# DDR_CTRL register map
Registers from a debugger description file.
Registers are 32-bit, access not given, no defined reset value unless marked. A register's access mark holds for its fields unless they carry their own. Addresses are absolute; registers are grouped by the start of their names; lines under a group give offsets from that group; [hi:lo] are bit positions; {n}, {i} and the like mark numbered series; 'fields as' and 'values as' point back to an identical list; <NAME> marks a mode.

## DENALI
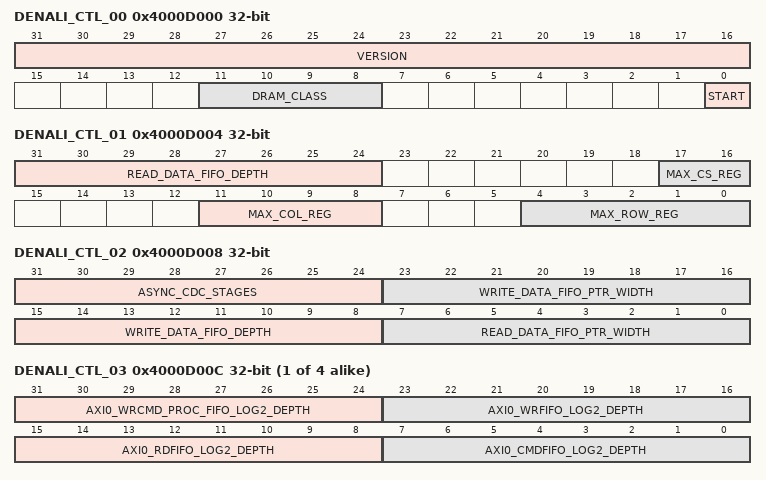
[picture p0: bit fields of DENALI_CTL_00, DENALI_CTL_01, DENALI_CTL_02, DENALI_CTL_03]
0x4000D000 DENALI_CTL_00
  [31:16] VERSION, [11:8] DRAM_CLASS, [0] START
0x4000D004 DENALI_CTL_01 ro
  [31:24] READ_DATA_FIFO_DEPTH, [17:16] MAX_CS_REG, [11:8] MAX_COL_REG, [4:0] MAX_ROW_REG
0x4000D008 DENALI_CTL_02 ro
  [31:24] ASYNC_CDC_STAGES, [23:16] WRITE_DATA_FIFO_PTR_WIDTH, [15:8] WRITE_DATA_FIFO_DEPTH, [7:0] READ_DATA_FIFO_PTR_WIDTH
{0x4000D000+4i} DENALI_CTL_{i:02} ro (i=3..6)
  [31:24] AXI{i-3}_WRCMD_PROC_FIFO_LOG2_DEPTH, [23:16] AXI{i-3}_WRFIFO_LOG2_DEPTH, [15:8] AXI{i-3}_RDFIFO_LOG2_DEPTH, [7:0] AXI{i-3}_CMDFIFO_LOG2_DEPTH
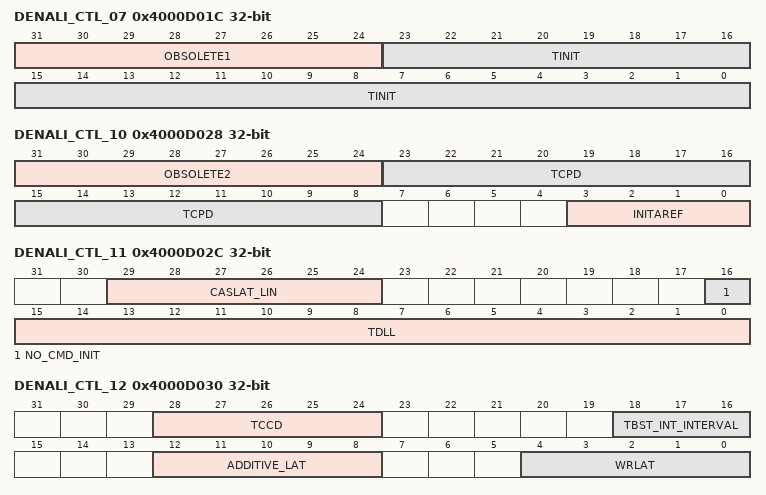
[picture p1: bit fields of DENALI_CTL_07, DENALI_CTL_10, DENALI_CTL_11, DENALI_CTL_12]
0x4000D01C DENALI_CTL_07
  [31:24] OBSOLETE1, [23:0] TINIT
0x4000D020 DENALI_CTL_08
  [31:0] TRST_PWRON
0x4000D024 DENALI_CTL_09
  [31:0] CKE_INACTIVE
0x4000D028 DENALI_CTL_10
  [31:24] OBSOLETE2, [23:8] TCPD, [3:0] INITAREF
0x4000D02C DENALI_CTL_11
  [29:24] CASLAT_LIN, [16] NO_CMD_INIT, [15:0] TDLL
0x4000D030 DENALI_CTL_12
  [28:24] TCCD, [18:16] TBST_INT_INTERVAL, [12:8] ADDITIVE_LAT, [4:0] WRLAT
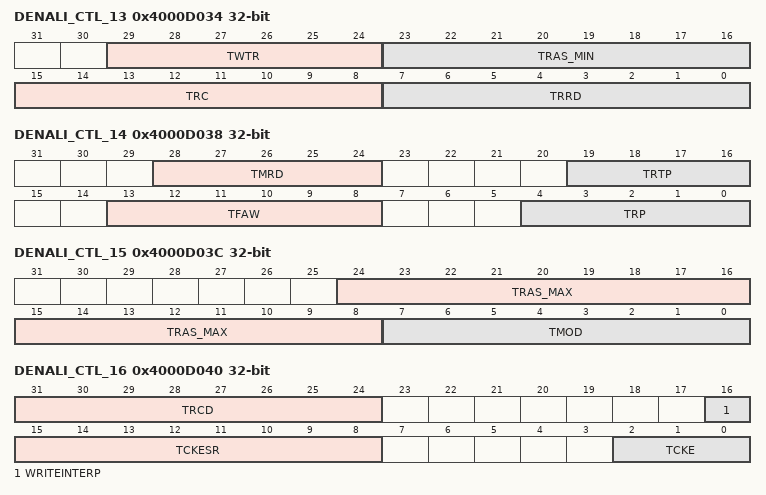
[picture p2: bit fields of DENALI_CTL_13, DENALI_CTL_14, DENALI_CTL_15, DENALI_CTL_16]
0x4000D034 DENALI_CTL_13
  [29:24] TWTR, [23:16] TRAS_MIN, [15:8] TRC, [7:0] TRRD
0x4000D038 DENALI_CTL_14
  [28:24] TMRD, [19:16] TRTP, [13:8] TFAW, [4:0] TRP
0x4000D03C DENALI_CTL_15
  [24:8] TRAS_MAX, [7:0] TMOD
0x4000D040 DENALI_CTL_16
  [31:24] TRCD, [16] WRITEINTERP, [15:8] TCKESR, [2:0] TCKE
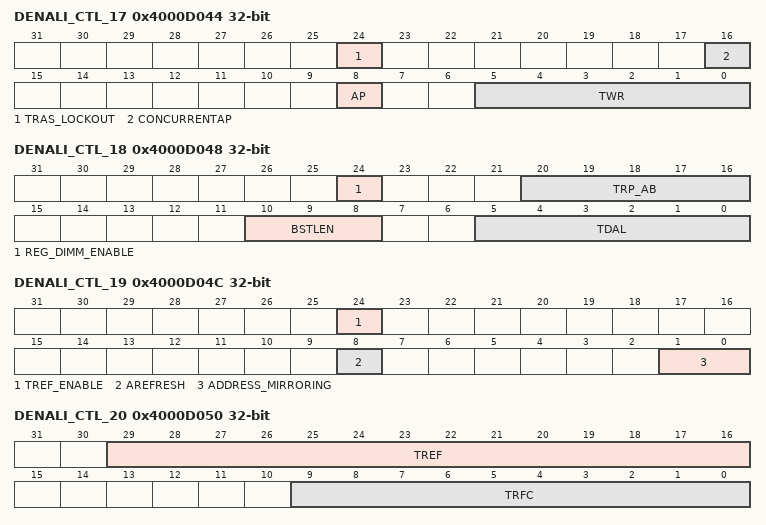
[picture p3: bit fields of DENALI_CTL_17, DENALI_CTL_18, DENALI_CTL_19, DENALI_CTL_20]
0x4000D044 DENALI_CTL_17
  [24] TRAS_LOCKOUT, [16] CONCURRENTAP, [8] AP, [5:0] TWR
0x4000D048 DENALI_CTL_18
  [24] REG_DIMM_ENABLE, [20:16] TRP_AB, [10:8] BSTLEN, [5:0] TDAL
0x4000D04C DENALI_CTL_19
  [24] TREF_ENABLE, [8] AREFRESH, [1:0] ADDRESS_MIRRORING
0x4000D050 DENALI_CTL_20
  [29:16] TREF, [9:0] TRFC
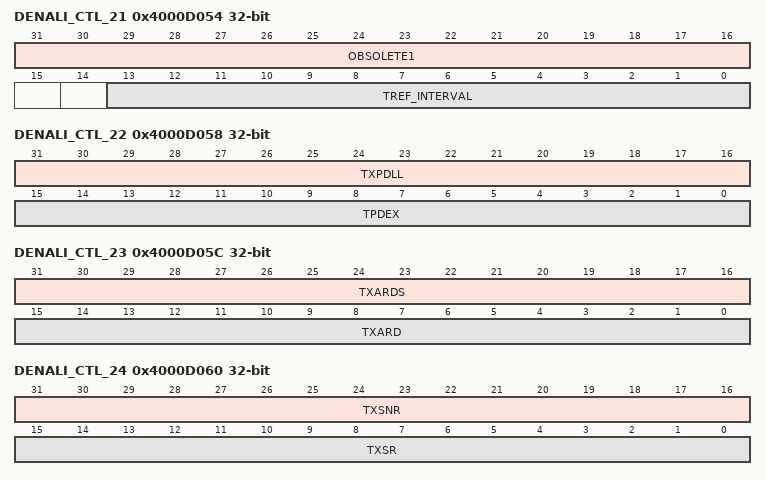
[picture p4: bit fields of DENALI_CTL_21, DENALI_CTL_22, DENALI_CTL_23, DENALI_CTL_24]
0x4000D054 DENALI_CTL_21
  [31:16] OBSOLETE1, [13:0] TREF_INTERVAL
0x4000D058 DENALI_CTL_22
  [31:16] TXPDLL, [15:0] TPDEX
0x4000D05C DENALI_CTL_23
  [31:16] TXARDS, [15:0] TXARD
0x4000D060 DENALI_CTL_24
  [31:16] TXSNR, [15:0] TXSR
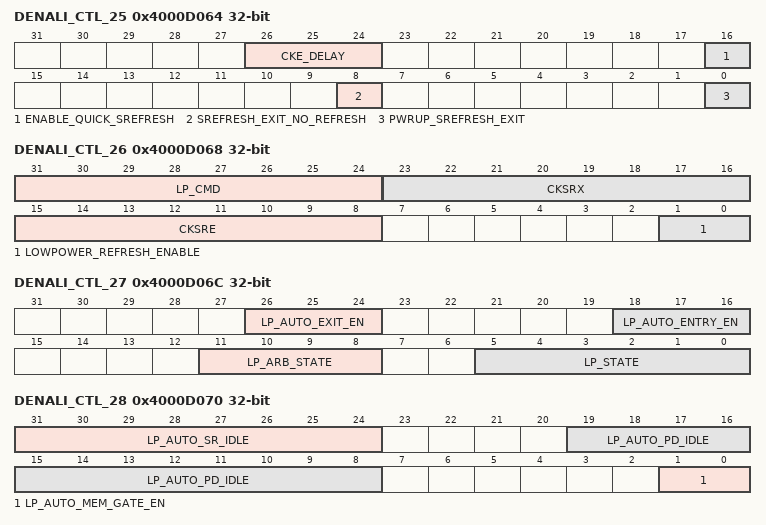
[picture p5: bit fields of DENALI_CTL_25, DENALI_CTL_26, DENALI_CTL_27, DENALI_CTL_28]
0x4000D064 DENALI_CTL_25
  [26:24] CKE_DELAY, [16] ENABLE_QUICK_SREFRESH, [8] SREFRESH_EXIT_NO_REFRESH, [0] PWRUP_SREFRESH_EXIT
0x4000D068 DENALI_CTL_26
  [31:24] LP_CMD, [23:16] CKSRX, [15:8] CKSRE, [1:0] LOWPOWER_REFRESH_ENABLE
0x4000D06C DENALI_CTL_27
  [26:24] LP_AUTO_EXIT_EN, [18:16] LP_AUTO_ENTRY_EN, [11:8] LP_ARB_STATE, [5:0] LP_STATE
0x4000D070 DENALI_CTL_28
  [31:24] LP_AUTO_SR_IDLE, [19:8] LP_AUTO_PD_IDLE, [1:0] LP_AUTO_MEM_GATE_EN
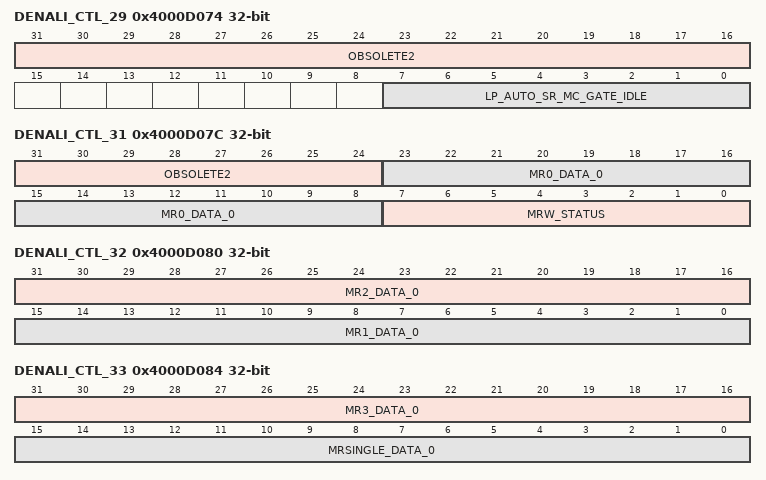
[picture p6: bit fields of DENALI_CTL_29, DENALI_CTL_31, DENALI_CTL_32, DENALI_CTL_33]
0x4000D074 DENALI_CTL_29
  [31:16] OBSOLETE2, [7:0] LP_AUTO_SR_MC_GATE_IDLE
0x4000D078 DENALI_CTL_30
  [25:0] WRITE_MODEREG
0x4000D07C DENALI_CTL_31
  [31:24] OBSOLETE2, [23:8] MR0_DATA_0, [7:0] MRW_STATUS
0x4000D080 DENALI_CTL_32
  [31:16] MR2_DATA_0, [15:0] MR1_DATA_0
0x4000D084 DENALI_CTL_33
  [31:16] MR3_DATA_0, [15:0] MRSINGLE_DATA_0
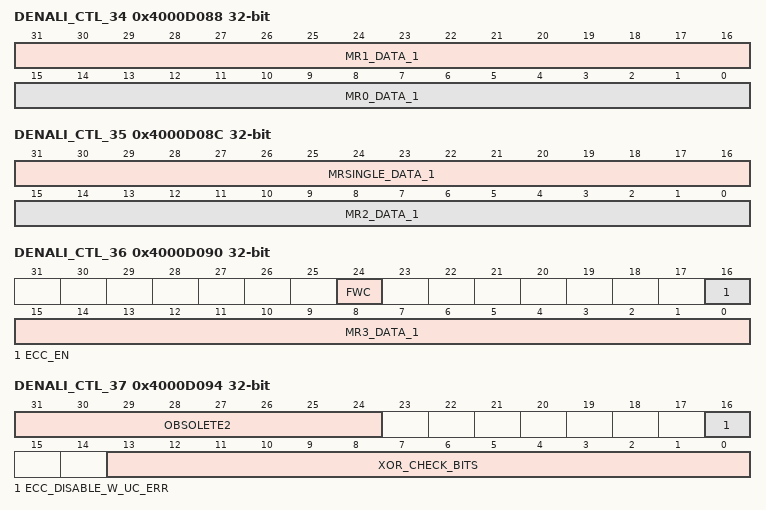
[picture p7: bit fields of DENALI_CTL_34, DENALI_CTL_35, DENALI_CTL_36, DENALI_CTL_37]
0x4000D088 DENALI_CTL_34
  [31:16] MR1_DATA_1, [15:0] MR0_DATA_1
0x4000D08C DENALI_CTL_35
  [31:16] MRSINGLE_DATA_1, [15:0] MR2_DATA_1
0x4000D090 DENALI_CTL_36
  [24] FWC, [16] ECC_EN, [15:0] MR3_DATA_1
0x4000D094 DENALI_CTL_37
  [31:24] OBSOLETE2, [16] ECC_DISABLE_W_UC_ERR, [13:0] XOR_CHECK_BITS
0x4000D098 DENALI_CTL_38 ro
  [31:0] ECC_U_ADDR
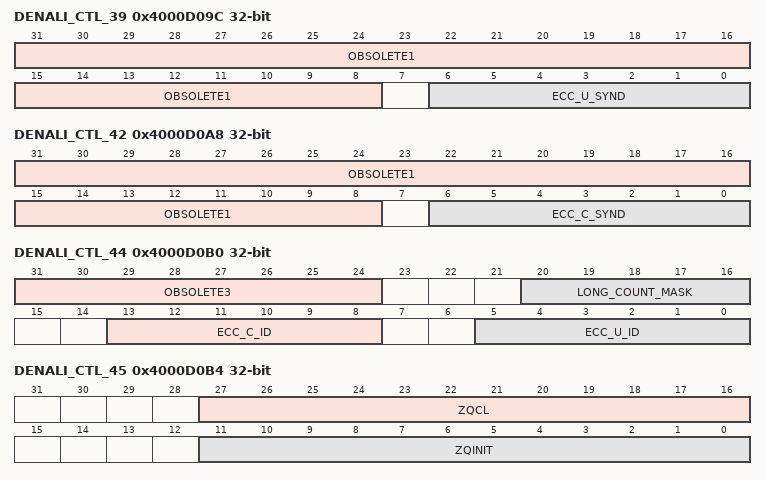
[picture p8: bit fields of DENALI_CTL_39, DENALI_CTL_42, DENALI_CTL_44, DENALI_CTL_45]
0x4000D09C DENALI_CTL_39 ro
  [31:8] OBSOLETE1, [6:0] ECC_U_SYND
0x4000D0A0 DENALI_CTL_40 ro
  [31:0] ECC_U_DATA
0x4000D0A4 DENALI_CTL_41 ro
  [31:0] ECC_C_ADDR
0x4000D0A8 DENALI_CTL_42 ro
  [31:8] OBSOLETE1, [6:0] ECC_C_SYND
0x4000D0AC DENALI_CTL_43 ro
  [31:0] ECC_C_DATA
0x4000D0B0 DENALI_CTL_44
  [31:24] OBSOLETE3, [20:16] LONG_COUNT_MASK, [13:8] ECC_C_ID, [5:0] ECC_U_ID
0x4000D0B4 DENALI_CTL_45
  [27:16] ZQCL, [11:0] ZQINIT
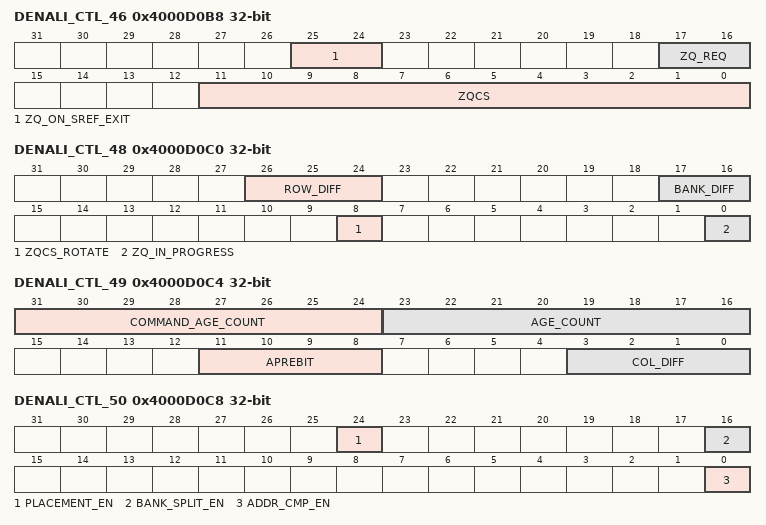
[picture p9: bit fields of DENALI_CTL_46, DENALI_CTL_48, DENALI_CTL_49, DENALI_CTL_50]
0x4000D0B8 DENALI_CTL_46
  [25:24] ZQ_ON_SREF_EXIT, [17:16] ZQ_REQ, [11:0] ZQCS
0x4000D0BC DENALI_CTL_47
  [31:0] ZQ_INTERVAL
0x4000D0C0 DENALI_CTL_48
  [26:24] ROW_DIFF, [17:16] BANK_DIFF, [8] ZQCS_ROTATE, [0] ZQ_IN_PROGRESS
0x4000D0C4 DENALI_CTL_49
  [31:24] COMMAND_AGE_COUNT, [23:16] AGE_COUNT, [11:8] APREBIT, [3:0] COL_DIFF
0x4000D0C8 DENALI_CTL_50
  [24] PLACEMENT_EN, [16] BANK_SPLIT_EN, [0] ADDR_CMP_EN
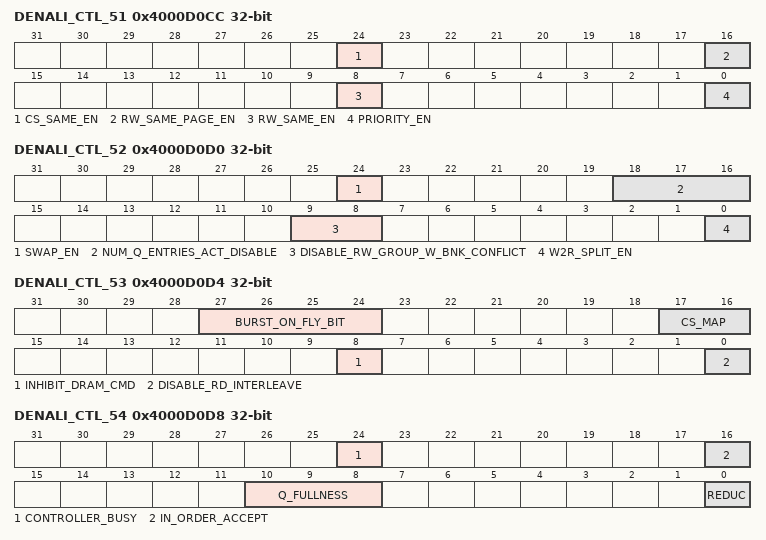
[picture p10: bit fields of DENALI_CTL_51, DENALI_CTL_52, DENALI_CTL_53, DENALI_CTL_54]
0x4000D0CC DENALI_CTL_51
  [24] CS_SAME_EN, [16] RW_SAME_PAGE_EN, [8] RW_SAME_EN, [0] PRIORITY_EN
0x4000D0D0 DENALI_CTL_52
  [24] SWAP_EN, [18:16] NUM_Q_ENTRIES_ACT_DISABLE, [9:8] DISABLE_RW_GROUP_W_BNK_CONFLICT, [0] W2R_SPLIT_EN
0x4000D0D4 DENALI_CTL_53
  [27:24] BURST_ON_FLY_BIT, [17:16] CS_MAP, [8] INHIBIT_DRAM_CMD, [0] DISABLE_RD_INTERLEAVE
0x4000D0D8 DENALI_CTL_54
  [24] CONTROLLER_BUSY, [16] IN_ORDER_ACCEPT, [10:8] Q_FULLNESS, [0] REDUC
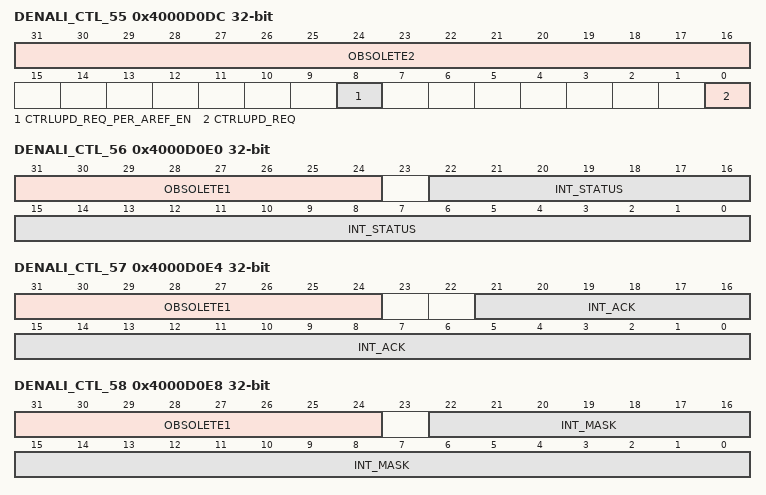
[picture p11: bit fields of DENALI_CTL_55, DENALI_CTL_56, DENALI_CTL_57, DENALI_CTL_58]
0x4000D0DC DENALI_CTL_55
  [31:16] OBSOLETE2, [8] CTRLUPD_REQ_PER_AREF_EN, [0] CTRLUPD_REQ
0x4000D0E0 DENALI_CTL_56 ro
  [31:24] OBSOLETE1, [22:0] INT_STATUS
0x4000D0E4 DENALI_CTL_57
  [31:24] OBSOLETE1, [21:0] INT_ACK
0x4000D0E8 DENALI_CTL_58
  [31:24] OBSOLETE1, [22:0] INT_MASK
0x4000D0EC DENALI_CTL_59 ro
  [31:0] OUT_OF_RANGE_ADDR
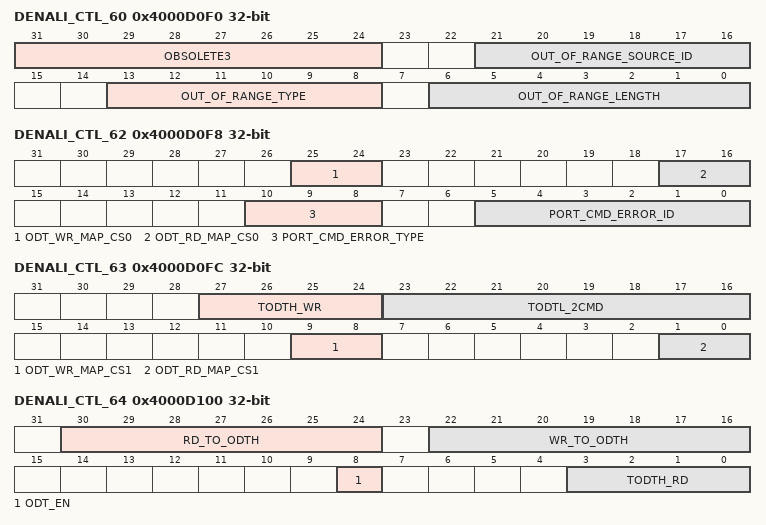
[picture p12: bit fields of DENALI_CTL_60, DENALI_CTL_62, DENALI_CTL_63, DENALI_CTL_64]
0x4000D0F0 DENALI_CTL_60 ro
  [31:24] OBSOLETE3, [21:16] OUT_OF_RANGE_SOURCE_ID, [13:8] OUT_OF_RANGE_TYPE, [6:0] OUT_OF_RANGE_LENGTH
0x4000D0F4 DENALI_CTL_61 ro
  [31:0] PORT_CMD_ERROR_ADDR
0x4000D0F8 DENALI_CTL_62
  [25:24] ODT_WR_MAP_CS0, [17:16] ODT_RD_MAP_CS0, [10:8] PORT_CMD_ERROR_TYPE, [5:0] PORT_CMD_ERROR_ID
0x4000D0FC DENALI_CTL_63
  [27:24] TODTH_WR, [23:16] TODTL_2CMD, [9:8] ODT_WR_MAP_CS1, [1:0] ODT_RD_MAP_CS1
0x4000D100 DENALI_CTL_64
  [30:24] RD_TO_ODTH, [22:16] WR_TO_ODTH, [8] ODT_EN, [3:0] TODTH_RD
0x4000D104 DENALI_CTL_65 ro
  [31:0] OBSOLETE0
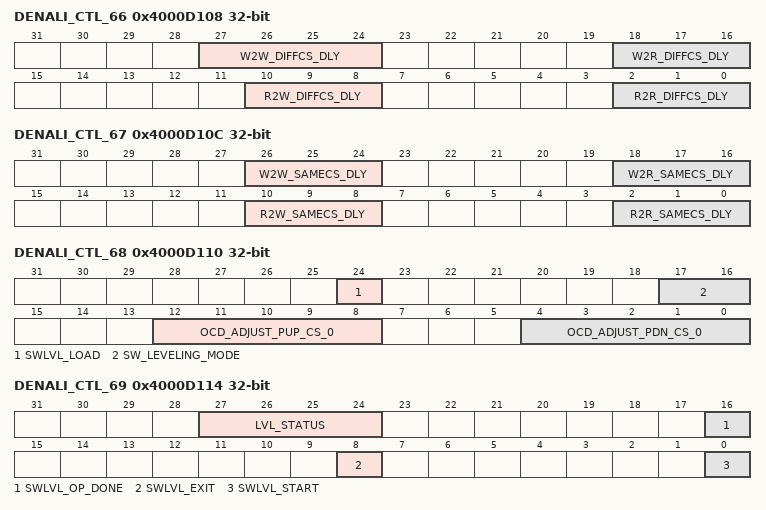
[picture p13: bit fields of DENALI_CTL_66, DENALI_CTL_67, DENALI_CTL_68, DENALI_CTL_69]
0x4000D108 DENALI_CTL_66
  [27:24] W2W_DIFFCS_DLY, [18:16] W2R_DIFFCS_DLY, [10:8] R2W_DIFFCS_DLY, [2:0] R2R_DIFFCS_DLY
0x4000D10C DENALI_CTL_67
  [26:24] W2W_SAMECS_DLY, [18:16] W2R_SAMECS_DLY, [10:8] R2W_SAMECS_DLY, [2:0] R2R_SAMECS_DLY
0x4000D110 DENALI_CTL_68
  [24] SWLVL_LOAD, [17:16] SW_LEVELING_MODE, [12:8] OCD_ADJUST_PUP_CS_0, [4:0] OCD_ADJUST_PDN_CS_0
0x4000D114 DENALI_CTL_69
  [27:24] LVL_STATUS, [16] SWLVL_OP_DONE, [8] SWLVL_EXIT, [0] SWLVL_START
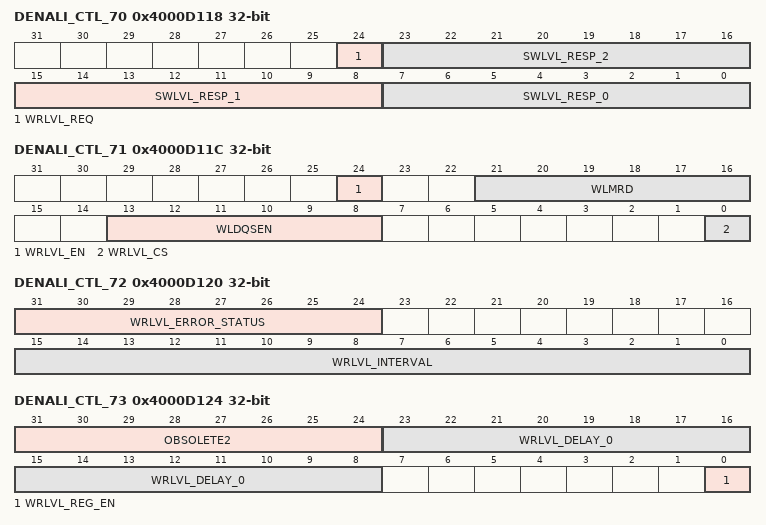
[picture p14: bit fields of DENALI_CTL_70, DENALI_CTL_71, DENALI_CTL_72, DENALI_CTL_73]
0x4000D118 DENALI_CTL_70
  [24] WRLVL_REQ, [23:16] SWLVL_RESP_2, [15:8] SWLVL_RESP_1, [7:0] SWLVL_RESP_0
0x4000D11C DENALI_CTL_71
  [24] WRLVL_EN, [21:16] WLMRD, [13:8] WLDQSEN, [0] WRLVL_CS
0x4000D120 DENALI_CTL_72
  [31:24] WRLVL_ERROR_STATUS, [15:0] WRLVL_INTERVAL
0x4000D124 DENALI_CTL_73
  [31:24] OBSOLETE2, [23:8] WRLVL_DELAY_0, [0] WRLVL_REG_EN
0x4000D128 DENALI_CTL_74
  [31:16] WRLVL_DELAY_2, [15:0] WRLVL_DELAY_1
0x4000D12C DENALI_CTL_75
  [24] RDLVL_EDGE, [16] RDLVL_CS, [8] RDLVL_GATE_REQ, [0] RDLVL_REQ
0x4000D130 DENALI_CTL_76
  [31:24] OBSOLETE3, [16] RDLVL_GATE_REG_EN, [8] RDLVL_REG_EN, [0] RDLVL_BEGIN_DELAY_EN
0x4000D134 DENALI_CTL_77 ro
  [31:16] RDLVL_END_DELAY_0, [15:0] RDLVL_BEGIN_DELAY_0
0x4000D138 DENALI_CTL_78
  [31:16] RDLVL_OFFSET_DELAY_0, [15:0] RDLVL_MIDPOINT_DELAY_0
0x4000D13C DENALI_CTL_79
  [31:24] OBSOLETE2, [23:8] RDLVL_DELAY_0, [0] RDLVL_OFFSET_DIR_0
0x4000D140 DENALI_CTL_80
  [31:16] RDLVL_BEGIN_DELAY_1, [15:0] RDLVL_GATE_DELAY_0
0x4000D144 DENALI_CTL_81 ro
  [31:16] RDLVL_MIDPOINT_DELAY_1, [15:0] RDLVL_END_DELAY_1
0x4000D148 DENALI_CTL_82
  [31:24] OBSOLETE2, [16] RDLVL_OFFSET_DIR_1, [15:0] RDLVL_OFFSET_DELAY_1
0x4000D14C DENALI_CTL_83
  [31:16] RDLVL_GATE_DELAY_1, [15:0] RDLVL_DELAY_1
0x4000D150 DENALI_CTL_84 ro
  [31:16] RDLVL_END_DELAY_2, [15:0] RDLVL_BEGIN_DELAY_2
0x4000D154 DENALI_CTL_85
  [31:16] RDLVL_OFFSET_DELAY_2, [15:0] RDLVL_MIDPOINT_DELAY_2
0x4000D158 DENALI_CTL_86
  [31:24] OBSOLETE2, [23:8] RDLVL_DELAY_2, [0] RDLVL_OFFSET_DIR_2
0x4000D15C DENALI_CTL_87
  [25:24] AXI0_W_PRIORITY, [17:16] AXI0_R_PRIORITY, [15:0] RDLVL_GATE_DELAY_2
0x4000D160 DENALI_CTL_88
  [25:24] AXI1_FIFO_TYPE_REG, [17:16] AXI1_W_PRIORITY, [9:8] AXI1_R_PRIORITY, [1:0] AXI0_FIFO_TYPE_REG
0x4000D164 DENALI_CTL_89
  [25:24] AXI3_R_PRIORITY, [17:16] AXI2_FIFO_TYPE_REG, [9:8] AXI2_W_PRIORITY, [1:0] AXI2_R_PRIORITY
0x4000D168 DENALI_CTL_90
  [24] PORT_ADDR_PROTECTION_EN, [23:16] OBSOLETE2, [9:8] AXI3_FIFO_TYPE_REG, [1:0] AXI3_W_PRIORITY
0x4000D16C DENALI_CTL_91
  [31:24] OBSOLETE1, [17:0] AXI0_START_ADDR_0
0x4000D170 DENALI_CTL_92
  [31:24] OBSOLETE1, [17:0] AXI0_END_ADDR_0
0x4000D174 DENALI_CTL_93
  [31:24] OBSOLETE1, [17:0] AXI0_START_ADDR_1
0x4000D178 DENALI_CTL_94
  [31:24] OBSOLETE1, [17:0] AXI0_END_ADDR_1
0x4000D17C DENALI_CTL_95
  [31:24] OBSOLETE1, [17:0] AXI0_START_ADDR_2
0x4000D180 DENALI_CTL_96
  [31:24] OBSOLETE1, [17:0] AXI0_END_ADDR_2
0x4000D184 DENALI_CTL_97
  [31:24] OBSOLETE1, [17:0] AXI0_START_ADDR_3
0x4000D188 DENALI_CTL_98
  [31:24] OBSOLETE1, [17:0] AXI0_END_ADDR_3
0x4000D18C DENALI_CTL_99
  [31:24] OBSOLETE1, [17:0] AXI0_START_ADDR_4
0x4000D190 DENALI_CTL_100
  [31:24] OBSOLETE1, [17:0] AXI0_END_ADDR_4
0x4000D194 DENALI_CTL_101
  [31:24] OBSOLETE1, [17:0] AXI0_START_ADDR_5
0x4000D198 DENALI_CTL_102
  [31:24] OBSOLETE1, [17:0] AXI0_END_ADDR_5
0x4000D19C DENALI_CTL_103
  [31:24] OBSOLETE1, [17:0] AXI0_START_ADDR_6
0x4000D1A0 DENALI_CTL_104
  [31:24] OBSOLETE1, [17:0] AXI0_END_ADDR_6
0x4000D1A4 DENALI_CTL_105
  [31:24] OBSOLETE1, [17:0] AXI0_START_ADDR_7
0x4000D1A8 DENALI_CTL_106
  [31:24] OBSOLETE1, [17:0] AXI0_END_ADDR_7
0x4000D1AC DENALI_CTL_107
  [31:24] OBSOLETE1, [17:0] AXI0_START_ADDR_8
0x4000D1B0 DENALI_CTL_108
  [31:24] OBSOLETE1, [17:0] AXI0_END_ADDR_8
0x4000D1B4 DENALI_CTL_109
  [31:24] OBSOLETE1, [17:0] AXI0_START_ADDR_9
0x4000D1B8 DENALI_CTL_110
  [31:24] OBSOLETE1, [17:0] AXI0_END_ADDR_9
0x4000D1BC DENALI_CTL_111
  [31:24] OBSOLETE1, [17:0] AXI0_START_ADDR_10
0x4000D1C0 DENALI_CTL_112
  [31:24] OBSOLETE1, [17:0] AXI0_END_ADDR_10
0x4000D1C4 DENALI_CTL_113
  [31:24] OBSOLETE1, [17:0] AXI0_START_ADDR_11
0x4000D1C8 DENALI_CTL_114
  [31:24] OBSOLETE1, [17:0] AXI0_END_ADDR_11
0x4000D1CC DENALI_CTL_115
  [31:24] OBSOLETE1, [17:0] AXI0_START_ADDR_12
0x4000D1D0 DENALI_CTL_116
  [31:24] OBSOLETE1, [17:0] AXI0_END_ADDR_12
0x4000D1D4 DENALI_CTL_117
  [31:24] OBSOLETE1, [17:0] AXI0_START_ADDR_13
0x4000D1D8 DENALI_CTL_118
  [31:24] OBSOLETE1, [17:0] AXI0_END_ADDR_13
0x4000D1DC DENALI_CTL_119
  [31:24] OBSOLETE1, [17:0] AXI0_START_ADDR_14
0x4000D1E0 DENALI_CTL_120
  [31:24] OBSOLETE1, [17:0] AXI0_END_ADDR_14
0x4000D1E4 DENALI_CTL_121
  [31:24] OBSOLETE1, [17:0] AXI0_START_ADDR_15
0x4000D1E8 DENALI_CTL_122
  [31:24] OBSOLETE1, [17:0] AXI0_END_ADDR_15
0x4000D1EC DENALI_CTL_123
  [31:24] OBSOLETE1, [17:0] AXI1_START_ADDR_0
0x4000D1F0 DENALI_CTL_124
  [31:24] OBSOLETE1, [17:0] AXI1_END_ADDR_0
0x4000D1F4 DENALI_CTL_125
  [31:24] OBSOLETE1, [17:0] AXI1_START_ADDR_1
0x4000D1F8 DENALI_CTL_126
  [31:24] OBSOLETE1, [17:0] AXI1_END_ADDR_1
0x4000D1FC DENALI_CTL_127
  [31:24] OBSOLETE1, [17:0] AXI1_START_ADDR_2
0x4000D200 DENALI_CTL_128
  [31:24] OBSOLETE1, [17:0] AXI1_END_ADDR_2
0x4000D204 DENALI_CTL_129
  [31:24] OBSOLETE1, [17:0] AXI1_START_ADDR_3
0x4000D208 DENALI_CTL_130
  [31:24] OBSOLETE1, [17:0] AXI1_END_ADDR_3
0x4000D20C DENALI_CTL_131
  [31:24] OBSOLETE1, [17:0] AXI1_START_ADDR_4
0x4000D210 DENALI_CTL_132
  [31:24] OBSOLETE1, [17:0] AXI1_END_ADDR_4
0x4000D214 DENALI_CTL_133
  [31:24] OBSOLETE1, [17:0] AXI1_START_ADDR_5
0x4000D218 DENALI_CTL_134
  [31:24] OBSOLETE1, [17:0] AXI1_END_ADDR_5
0x4000D21C DENALI_CTL_135
  [31:24] OBSOLETE1, [17:0] AXI1_START_ADDR_6
0x4000D220 DENALI_CTL_136
  [31:24] OBSOLETE1, [17:0] AXI1_END_ADDR_6
0x4000D224 DENALI_CTL_137
  [31:24] OBSOLETE1, [17:0] AXI1_START_ADDR_7
0x4000D228 DENALI_CTL_138
  [31:24] OBSOLETE1, [17:0] AXI1_END_ADDR_7
0x4000D22C DENALI_CTL_139
  [31:24] OBSOLETE1, [17:0] AXI1_START_ADDR_8
0x4000D230 DENALI_CTL_140
  [31:24] OBSOLETE1, [17:0] AXI1_END_ADDR_8
0x4000D234 DENALI_CTL_141
  [31:24] OBSOLETE1, [17:0] AXI1_START_ADDR_9
0x4000D238 DENALI_CTL_142
  [31:24] OBSOLETE1, [17:0] AXI1_END_ADDR_9
0x4000D23C DENALI_CTL_143
  [31:24] OBSOLETE1, [17:0] AXI1_START_ADDR_10
0x4000D240 DENALI_CTL_144
  [31:24] OBSOLETE1, [17:0] AXI1_END_ADDR_10
0x4000D244 DENALI_CTL_145
  [31:24] OBSOLETE1, [17:0] AXI1_START_ADDR_11
0x4000D248 DENALI_CTL_146
  [31:24] OBSOLETE1, [17:0] AXI1_END_ADDR_11
0x4000D24C DENALI_CTL_147
  [31:24] OBSOLETE1, [17:0] AXI1_START_ADDR_12
0x4000D250 DENALI_CTL_148
  [31:24] OBSOLETE1, [17:0] AXI1_END_ADDR_12
0x4000D254 DENALI_CTL_149
  [31:24] OBSOLETE1, [17:0] AXI1_START_ADDR_13
0x4000D258 DENALI_CTL_150
  [31:24] OBSOLETE1, [17:0] AXI1_END_ADDR_13
0x4000D25C DENALI_CTL_151
  [31:24] OBSOLETE1, [17:0] AXI1_START_ADDR_14
0x4000D260 DENALI_CTL_152
  [31:24] OBSOLETE1, [17:0] AXI1_END_ADDR_14
0x4000D264 DENALI_CTL_153
  [31:24] OBSOLETE1, [17:0] AXI1_START_ADDR_15
0x4000D268 DENALI_CTL_154
  [31:24] OBSOLETE1, [17:0] AXI1_END_ADDR_15
0x4000D26C DENALI_CTL_155
  [31:24] OBSOLETE1, [17:0] AXI2_START_ADDR_0
0x4000D270 DENALI_CTL_156
  [31:24] OBSOLETE1, [17:0] AXI2_END_ADDR_0
0x4000D274 DENALI_CTL_157
  [31:24] OBSOLETE1, [17:0] AXI2_START_ADDR_1
0x4000D278 DENALI_CTL_158
  [31:24] OBSOLETE1, [17:0] AXI2_END_ADDR_1
0x4000D27C DENALI_CTL_159
  [31:24] OBSOLETE1, [17:0] AXI2_START_ADDR_2
0x4000D280 DENALI_CTL_160
  [31:24] OBSOLETE1, [17:0] AXI2_END_ADDR_2
0x4000D284 DENALI_CTL_161
  [31:24] OBSOLETE1, [17:0] AXI2_START_ADDR_3
0x4000D288 DENALI_CTL_162
  [31:24] OBSOLETE1, [17:0] AXI2_END_ADDR_3
0x4000D28C DENALI_CTL_163
  [31:24] OBSOLETE1, [17:0] AXI2_START_ADDR_4
0x4000D290 DENALI_CTL_164
  [31:24] OBSOLETE1, [17:0] AXI2_END_ADDR_4
0x4000D294 DENALI_CTL_165
  [31:24] OBSOLETE1, [17:0] AXI2_START_ADDR_5
0x4000D298 DENALI_CTL_166
  [31:24] OBSOLETE1, [17:0] AXI2_END_ADDR_5
0x4000D29C DENALI_CTL_167
  [31:24] OBSOLETE1, [17:0] AXI2_START_ADDR_6
0x4000D2A0 DENALI_CTL_168
  [31:24] OBSOLETE1, [17:0] AXI2_END_ADDR_6
0x4000D2A4 DENALI_CTL_169
  [31:24] OBSOLETE1, [17:0] AXI2_START_ADDR_7
0x4000D2A8 DENALI_CTL_170
  [31:24] OBSOLETE1, [17:0] AXI2_END_ADDR_7
0x4000D2AC DENALI_CTL_171
  [31:24] OBSOLETE1, [17:0] AXI2_START_ADDR_8
0x4000D2B0 DENALI_CTL_172
  [31:24] OBSOLETE1, [17:0] AXI2_END_ADDR_8
0x4000D2B4 DENALI_CTL_173
  [31:24] OBSOLETE1, [17:0] AXI2_START_ADDR_9
0x4000D2B8 DENALI_CTL_174
  [31:24] OBSOLETE1, [17:0] AXI2_END_ADDR_9
0x4000D2BC DENALI_CTL_175
  [31:24] OBSOLETE1, [17:0] AXI2_START_ADDR_10
0x4000D2C0 DENALI_CTL_176
  [31:24] OBSOLETE1, [17:0] AXI2_END_ADDR_10
0x4000D2C4 DENALI_CTL_177
  [31:24] OBSOLETE1, [17:0] AXI2_START_ADDR_11
0x4000D2C8 DENALI_CTL_178
  [31:24] OBSOLETE1, [17:0] AXI2_END_ADDR_11
0x4000D2CC DENALI_CTL_179
  [31:24] OBSOLETE1, [17:0] AXI2_START_ADDR_12
0x4000D2D0 DENALI_CTL_180
  [31:24] OBSOLETE1, [17:0] AXI2_END_ADDR_12
0x4000D2D4 DENALI_CTL_181
  [31:24] OBSOLETE1, [17:0] AXI2_START_ADDR_13
0x4000D2D8 DENALI_CTL_182
  [31:24] OBSOLETE1, [17:0] AXI2_END_ADDR_13
0x4000D2DC DENALI_CTL_183
  [31:24] OBSOLETE1, [17:0] AXI2_START_ADDR_14
0x4000D2E0 DENALI_CTL_184
  [31:24] OBSOLETE1, [17:0] AXI2_END_ADDR_14
0x4000D2E4 DENALI_CTL_185
  [31:24] OBSOLETE1, [17:0] AXI2_START_ADDR_15
0x4000D2E8 DENALI_CTL_186
  [31:24] OBSOLETE1, [17:0] AXI2_END_ADDR_15
0x4000D2EC DENALI_CTL_187
  [31:24] OBSOLETE1, [17:0] AXI3_START_ADDR_0
0x4000D2F0 DENALI_CTL_188
  [31:24] OBSOLETE1, [17:0] AXI3_END_ADDR_0
0x4000D2F4 DENALI_CTL_189
  [31:24] OBSOLETE1, [17:0] AXI3_START_ADDR_1
0x4000D2F8 DENALI_CTL_190
  [31:24] OBSOLETE1, [17:0] AXI3_END_ADDR_1
0x4000D2FC DENALI_CTL_191
  [31:24] OBSOLETE1, [17:0] AXI3_START_ADDR_2
0x4000D300 DENALI_CTL_192
  [31:24] OBSOLETE1, [17:0] AXI3_END_ADDR_2
0x4000D304 DENALI_CTL_193
  [31:24] OBSOLETE1, [17:0] AXI3_START_ADDR_3
0x4000D308 DENALI_CTL_194
  [31:24] OBSOLETE1, [17:0] AXI3_END_ADDR_3
0x4000D30C DENALI_CTL_195
  [31:24] OBSOLETE1, [17:0] AXI3_START_ADDR_4
0x4000D310 DENALI_CTL_196
  [31:24] OBSOLETE1, [17:0] AXI3_END_ADDR_4
0x4000D314 DENALI_CTL_197
  [31:24] OBSOLETE1, [17:0] AXI3_START_ADDR_5
0x4000D318 DENALI_CTL_198
  [31:24] OBSOLETE1, [17:0] AXI3_END_ADDR_5
0x4000D31C DENALI_CTL_199
  [31:24] OBSOLETE1, [17:0] AXI3_START_ADDR_6
0x4000D320 DENALI_CTL_200
  [31:24] OBSOLETE1, [17:0] AXI3_END_ADDR_6
0x4000D324 DENALI_CTL_201
  [31:24] OBSOLETE1, [17:0] AXI3_START_ADDR_7
0x4000D328 DENALI_CTL_202
  [31:24] OBSOLETE1, [17:0] AXI3_END_ADDR_7
0x4000D32C DENALI_CTL_203
  [31:24] OBSOLETE1, [17:0] AXI3_START_ADDR_8
0x4000D330 DENALI_CTL_204
  [31:24] OBSOLETE1, [17:0] AXI3_END_ADDR_8
0x4000D334 DENALI_CTL_205
  [31:24] OBSOLETE1, [17:0] AXI3_START_ADDR_9
0x4000D338 DENALI_CTL_206
  [31:24] OBSOLETE1, [17:0] AXI3_END_ADDR_9
0x4000D33C DENALI_CTL_207
  [31:24] OBSOLETE1, [17:0] AXI3_START_ADDR_10
0x4000D340 DENALI_CTL_208
  [31:24] OBSOLETE1, [17:0] AXI3_END_ADDR_10
0x4000D344 DENALI_CTL_209
  [31:24] OBSOLETE1, [17:0] AXI3_START_ADDR_11
0x4000D348 DENALI_CTL_210
  [31:24] OBSOLETE1, [17:0] AXI3_END_ADDR_11
0x4000D34C DENALI_CTL_211
  [31:24] OBSOLETE1, [17:0] AXI3_START_ADDR_12
0x4000D350 DENALI_CTL_212
  [31:24] OBSOLETE1, [17:0] AXI3_END_ADDR_12
0x4000D354 DENALI_CTL_213
  [31:24] OBSOLETE1, [17:0] AXI3_START_ADDR_13
0x4000D358 DENALI_CTL_214
  [31:24] OBSOLETE1, [17:0] AXI3_END_ADDR_13
0x4000D35C DENALI_CTL_215
  [31:24] OBSOLETE1, [17:0] AXI3_START_ADDR_14
0x4000D360 DENALI_CTL_216
  [31:24] OBSOLETE1, [17:0] AXI3_END_ADDR_14
0x4000D364 DENALI_CTL_217
  [31:24] OBSOLETE1, [17:0] AXI3_START_ADDR_15
0x4000D368 DENALI_CTL_218
  [25:24] AXI0_RANGE_PROT_BITS_0, [17:0] AXI3_END_ADDR_15
0x4000D36C DENALI_CTL_219
  [31:16] AXI0_RANGE_WID_CHECK_BITS_0, [15:0] AXI0_RANGE_RID_CHECK_BITS_0
0x4000D370 DENALI_CTL_220
  [31:24] OBSOLETE3, [17:16] AXI0_RANGE_PROT_BITS_1, [11:8] AXI0_RANGE_WID_CHECK_BITS_ID_LOOKUP_0, [3:0] AXI0_RANGE_RID_CHECK_BITS_ID_LOOKUP_0
0x4000D374 DENALI_CTL_221
  [31:16] AXI0_RANGE_WID_CHECK_BITS_1, [15:0] AXI0_RANGE_RID_CHECK_BITS_1
0x4000D378 DENALI_CTL_222
  [31:24] OBSOLETE3, [17:16] AXI0_RANGE_PROT_BITS_2, [11:8] AXI0_RANGE_WID_CHECK_BITS_ID_LOOKUP_1, [3:0] AXI0_RANGE_RID_CHECK_BITS_ID_LOOKUP_1
0x4000D37C DENALI_CTL_223
  [31:16] AXI0_RANGE_WID_CHECK_BITS_2, [15:0] AXI0_RANGE_RID_CHECK_BITS_2
0x4000D380 DENALI_CTL_224
  [31:24] OBSOLETE3, [17:16] AXI0_RANGE_PROT_BITS_3, [11:8] AXI0_RANGE_WID_CHECK_BITS_ID_LOOKUP_2, [3:0] AXI0_RANGE_RID_CHECK_BITS_ID_LOOKUP_2
0x4000D384 DENALI_CTL_225
  [31:16] AXI0_RANGE_WID_CHECK_BITS_3, [15:0] AXI0_RANGE_RID_CHECK_BITS_3
0x4000D388 DENALI_CTL_226
  [31:24] OBSOLETE3, [17:16] AXI0_RANGE_PROT_BITS_4, [11:8] AXI0_RANGE_WID_CHECK_BITS_ID_LOOKUP_3, [3:0] AXI0_RANGE_RID_CHECK_BITS_ID_LOOKUP_3
0x4000D38C DENALI_CTL_227
  [31:16] AXI0_RANGE_WID_CHECK_BITS_4, [15:0] AXI0_RANGE_RID_CHECK_BITS_4
0x4000D390 DENALI_CTL_228
  [31:24] OBSOLETE3, [17:16] AXI0_RANGE_PROT_BITS_5, [11:8] AXI0_RANGE_WID_CHECK_BITS_ID_LOOKUP_4, [3:0] AXI0_RANGE_RID_CHECK_BITS_ID_LOOKUP_4
0x4000D394 DENALI_CTL_229
  [31:16] AXI0_RANGE_WID_CHECK_BITS_5, [15:0] AXI0_RANGE_RID_CHECK_BITS_5
0x4000D398 DENALI_CTL_230
  [31:24] OBSOLETE3, [17:16] AXI0_RANGE_PROT_BITS_6, [11:8] AXI0_RANGE_WID_CHECK_BITS_ID_LOOKUP_5, [3:0] AXI0_RANGE_RID_CHECK_BITS_ID_LOOKUP_5
0x4000D39C DENALI_CTL_231
  [31:16] AXI0_RANGE_WID_CHECK_BITS_6, [15:0] AXI0_RANGE_RID_CHECK_BITS_6
0x4000D3A0 DENALI_CTL_232
  [31:24] OBSOLETE3, [17:16] AXI0_RANGE_PROT_BITS_7, [11:8] AXI0_RANGE_WID_CHECK_BITS_ID_LOOKUP_6, [3:0] AXI0_RANGE_RID_CHECK_BITS_ID_LOOKUP_6
0x4000D3A4 DENALI_CTL_233
  [31:16] AXI0_RANGE_WID_CHECK_BITS_7, [15:0] AXI0_RANGE_RID_CHECK_BITS_7
0x4000D3A8 DENALI_CTL_234
  [31:24] OBSOLETE3, [17:16] AXI0_RANGE_PROT_BITS_8, [11:8] AXI0_RANGE_WID_CHECK_BITS_ID_LOOKUP_7, [3:0] AXI0_RANGE_RID_CHECK_BITS_ID_LOOKUP_7
0x4000D3AC DENALI_CTL_235
  [31:16] AXI0_RANGE_WID_CHECK_BITS_8, [15:0] AXI0_RANGE_RID_CHECK_BITS_8
0x4000D3B0 DENALI_CTL_236
  [31:24] OBSOLETE3, [17:16] AXI0_RANGE_PROT_BITS_9, [11:8] AXI0_RANGE_WID_CHECK_BITS_ID_LOOKUP_8, [3:0] AXI0_RANGE_RID_CHECK_BITS_ID_LOOKUP_8
0x4000D3B4 DENALI_CTL_237
  [31:16] AXI0_RANGE_WID_CHECK_BITS_9, [15:0] AXI0_RANGE_RID_CHECK_BITS_9
0x4000D3B8 DENALI_CTL_238
  [31:24] OBSOLETE3, [17:16] AXI0_RANGE_PROT_BITS_10, [11:8] AXI0_RANGE_WID_CHECK_BITS_ID_LOOKUP_9, [3:0] AXI0_RANGE_RID_CHECK_BITS_ID_LOOKUP_9
0x4000D3BC DENALI_CTL_239
  [31:16] AXI0_RANGE_WID_CHECK_BITS_10, [15:0] AXI0_RANGE_RID_CHECK_BITS_10
0x4000D3C0 DENALI_CTL_240
  [31:24] OBSOLETE3, [17:16] AXI0_RANGE_PROT_BITS_11, [11:8] AXI0_RANGE_WID_CHECK_BITS_ID_LOOKUP_10, [3:0] AXI0_RANGE_RID_CHECK_BITS_ID_LOOKUP_10
0x4000D3C4 DENALI_CTL_241
  [31:16] AXI0_RANGE_WID_CHECK_BITS_11, [15:0] AXI0_RANGE_RID_CHECK_BITS_11
0x4000D3C8 DENALI_CTL_242
  [31:24] OBSOLETE3, [17:16] AXI0_RANGE_PROT_BITS_12, [11:8] AXI0_RANGE_WID_CHECK_BITS_ID_LOOKUP_11, [3:0] AXI0_RANGE_RID_CHECK_BITS_ID_LOOKUP_11
0x4000D3CC DENALI_CTL_243
  [31:16] AXI0_RANGE_WID_CHECK_BITS_12, [15:0] AXI0_RANGE_RID_CHECK_BITS_12
0x4000D3D0 DENALI_CTL_244
  [31:24] OBSOLETE3, [17:16] AXI0_RANGE_PROT_BITS_13, [11:8] AXI0_RANGE_WID_CHECK_BITS_ID_LOOKUP_12, [3:0] AXI0_RANGE_RID_CHECK_BITS_ID_LOOKUP_12
0x4000D3D4 DENALI_CTL_245
  [31:16] AXI0_RANGE_WID_CHECK_BITS_13, [15:0] AXI0_RANGE_RID_CHECK_BITS_13
0x4000D3D8 DENALI_CTL_246
  [31:24] OBSOLETE3, [17:16] AXI0_RANGE_PROT_BITS_14, [11:8] AXI0_RANGE_WID_CHECK_BITS_ID_LOOKUP_13, [3:0] AXI0_RANGE_RID_CHECK_BITS_ID_LOOKUP_13
0x4000D3DC DENALI_CTL_247
  [31:16] AXI0_RANGE_WID_CHECK_BITS_14, [15:0] AXI0_RANGE_RID_CHECK_BITS_14
0x4000D3E0 DENALI_CTL_248
  [31:24] OBSOLETE3, [17:16] AXI0_RANGE_PROT_BITS_15, [11:8] AXI0_RANGE_WID_CHECK_BITS_ID_LOOKUP_14, [3:0] AXI0_RANGE_RID_CHECK_BITS_ID_LOOKUP_14
0x4000D3E4 DENALI_CTL_249
  [31:16] AXI0_RANGE_WID_CHECK_BITS_15, [15:0] AXI0_RANGE_RID_CHECK_BITS_15
0x4000D3E8 DENALI_CTL_250
  [31:24] OBSOLETE3, [17:16] AXI1_RANGE_PROT_BITS_0, [11:8] AXI0_RANGE_WID_CHECK_BITS_ID_LOOKUP_15, [3:0] AXI0_RANGE_RID_CHECK_BITS_ID_LOOKUP_15
0x4000D3EC DENALI_CTL_251
  [31:16] AXI1_RANGE_WID_CHECK_BITS_0, [15:0] AXI1_RANGE_RID_CHECK_BITS_0
0x4000D3F0 DENALI_CTL_252
  [31:24] OBSOLETE3, [17:16] AXI1_RANGE_PROT_BITS_1, [11:8] AXI1_RANGE_WID_CHECK_BITS_ID_LOOKUP_0, [3:0] AXI1_RANGE_RID_CHECK_BITS_ID_LOOKUP_0
0x4000D3F4 DENALI_CTL_253
  [31:16] AXI1_RANGE_WID_CHECK_BITS_1, [15:0] AXI1_RANGE_RID_CHECK_BITS_1
0x4000D3F8 DENALI_CTL_254
  [31:24] OBSOLETE3, [17:16] AXI1_RANGE_PROT_BITS_2, [11:8] AXI1_RANGE_WID_CHECK_BITS_ID_LOOKUP_1, [3:0] AXI1_RANGE_RID_CHECK_BITS_ID_LOOKUP_1
0x4000D3FC DENALI_CTL_255
  [31:16] AXI1_RANGE_WID_CHECK_BITS_2, [15:0] AXI1_RANGE_RID_CHECK_BITS_2
0x4000D400 DENALI_CTL_256
  [31:24] OBSOLETE3, [17:16] AXI1_RANGE_PROT_BITS_3, [11:8] AXI1_RANGE_WID_CHECK_BITS_ID_LOOKUP_2, [3:0] AXI1_RANGE_RID_CHECK_BITS_ID_LOOKUP_2
0x4000D404 DENALI_CTL_257
  [31:16] AXI1_RANGE_WID_CHECK_BITS_3, [15:0] AXI1_RANGE_RID_CHECK_BITS_3
0x4000D408 DENALI_CTL_258
  [31:24] OBSOLETE3, [17:16] AXI1_RANGE_PROT_BITS_4, [11:8] AXI1_RANGE_WID_CHECK_BITS_ID_LOOKUP_3, [3:0] AXI1_RANGE_RID_CHECK_BITS_ID_LOOKUP_3
0x4000D40C DENALI_CTL_259
  [31:16] AXI1_RANGE_WID_CHECK_BITS_4, [15:0] AXI1_RANGE_RID_CHECK_BITS_4
0x4000D410 DENALI_CTL_260
  [31:24] OBSOLETE3, [17:16] AXI1_RANGE_PROT_BITS_5, [11:8] AXI1_RANGE_WID_CHECK_BITS_ID_LOOKUP_4, [3:0] AXI1_RANGE_RID_CHECK_BITS_ID_LOOKUP_4
0x4000D414 DENALI_CTL_261
  [31:16] AXI1_RANGE_WID_CHECK_BITS_5, [15:0] AXI1_RANGE_RID_CHECK_BITS_5
0x4000D418 DENALI_CTL_262
  [31:24] OBSOLETE3, [17:16] AXI1_RANGE_PROT_BITS_6, [11:8] AXI1_RANGE_WID_CHECK_BITS_ID_LOOKUP_5, [3:0] AXI1_RANGE_RID_CHECK_BITS_ID_LOOKUP_5
0x4000D41C DENALI_CTL_263
  [31:16] AXI1_RANGE_WID_CHECK_BITS_6, [15:0] AXI1_RANGE_RID_CHECK_BITS_6
0x4000D420 DENALI_CTL_264
  [31:24] OBSOLETE3, [17:16] AXI1_RANGE_PROT_BITS_7, [11:8] AXI1_RANGE_WID_CHECK_BITS_ID_LOOKUP_6, [3:0] AXI1_RANGE_RID_CHECK_BITS_ID_LOOKUP_6
0x4000D424 DENALI_CTL_265
  [31:16] AXI1_RANGE_WID_CHECK_BITS_7, [15:0] AXI1_RANGE_RID_CHECK_BITS_7
0x4000D428 DENALI_CTL_266
  [31:24] OBSOLETE3, [17:16] AXI1_RANGE_PROT_BITS_8, [11:8] AXI1_RANGE_WID_CHECK_BITS_ID_LOOKUP_7, [3:0] AXI1_RANGE_RID_CHECK_BITS_ID_LOOKUP_7
0x4000D42C DENALI_CTL_267
  [31:16] AXI1_RANGE_WID_CHECK_BITS_8, [15:0] AXI1_RANGE_RID_CHECK_BITS_8
0x4000D430 DENALI_CTL_268
  [31:24] OBSOLETE3, [17:16] AXI1_RANGE_PROT_BITS_9, [11:8] AXI1_RANGE_WID_CHECK_BITS_ID_LOOKUP_8, [3:0] AXI1_RANGE_RID_CHECK_BITS_ID_LOOKUP_8
0x4000D434 DENALI_CTL_269
  [31:16] AXI1_RANGE_WID_CHECK_BITS_9, [15:0] AXI1_RANGE_RID_CHECK_BITS_9
0x4000D438 DENALI_CTL_270
  [31:24] OBSOLETE3, [17:16] AXI1_RANGE_PROT_BITS_10, [11:8] AXI1_RANGE_WID_CHECK_BITS_ID_LOOKUP_9, [3:0] AXI1_RANGE_RID_CHECK_BITS_ID_LOOKUP_9
0x4000D43C DENALI_CTL_271
  [31:16] AXI1_RANGE_WID_CHECK_BITS_10, [15:0] AXI1_RANGE_RID_CHECK_BITS_10
0x4000D440 DENALI_CTL_272
  [31:24] OBSOLETE3, [17:16] AXI1_RANGE_PROT_BITS_11, [11:8] AXI1_RANGE_WID_CHECK_BITS_ID_LOOKUP_10, [3:0] AXI1_RANGE_RID_CHECK_BITS_ID_LOOKUP_10
0x4000D444 DENALI_CTL_273
  [31:16] AXI1_RANGE_WID_CHECK_BITS_11, [15:0] AXI1_RANGE_RID_CHECK_BITS_11
0x4000D448 DENALI_CTL_274
  [31:24] OBSOLETE3, [17:16] AXI1_RANGE_PROT_BITS_12, [11:8] AXI1_RANGE_WID_CHECK_BITS_ID_LOOKUP_11, [3:0] AXI1_RANGE_RID_CHECK_BITS_ID_LOOKUP_11
0x4000D44C DENALI_CTL_275
  [31:16] AXI1_RANGE_WID_CHECK_BITS_12, [15:0] AXI1_RANGE_RID_CHECK_BITS_12
0x4000D450 DENALI_CTL_276
  [31:24] OBSOLETE3, [17:16] AXI1_RANGE_PROT_BITS_13, [11:8] AXI1_RANGE_WID_CHECK_BITS_ID_LOOKUP_12, [3:0] AXI1_RANGE_RID_CHECK_BITS_ID_LOOKUP_12
0x4000D454 DENALI_CTL_277
  [31:16] AXI1_RANGE_WID_CHECK_BITS_13, [15:0] AXI1_RANGE_RID_CHECK_BITS_13
0x4000D458 DENALI_CTL_278
  [31:24] OBSOLETE3, [17:16] AXI1_RANGE_PROT_BITS_14, [11:8] AXI1_RANGE_WID_CHECK_BITS_ID_LOOKUP_13, [3:0] AXI1_RANGE_RID_CHECK_BITS_ID_LOOKUP_13
0x4000D45C DENALI_CTL_279
  [31:16] AXI1_RANGE_WID_CHECK_BITS_14, [15:0] AXI1_RANGE_RID_CHECK_BITS_14
0x4000D460 DENALI_CTL_280
  [31:24] OBSOLETE3, [17:16] AXI1_RANGE_PROT_BITS_15, [11:8] AXI1_RANGE_WID_CHECK_BITS_ID_LOOKUP_14, [3:0] AXI1_RANGE_RID_CHECK_BITS_ID_LOOKUP_14
0x4000D464 DENALI_CTL_281
  [31:16] AXI1_RANGE_WID_CHECK_BITS_15, [15:0] AXI1_RANGE_RID_CHECK_BITS_15
0x4000D468 DENALI_CTL_282
  [31:24] OBSOLETE3, [17:16] AXI2_RANGE_PROT_BITS_0, [11:8] AXI1_RANGE_WID_CHECK_BITS_ID_LOOKUP_15, [3:0] AXI1_RANGE_RID_CHECK_BITS_ID_LOOKUP_15
0x4000D46C DENALI_CTL_283
  [31:16] AXI2_RANGE_WID_CHECK_BITS_0, [15:0] AXI2_RANGE_RID_CHECK_BITS_0
0x4000D470 DENALI_CTL_284
  [31:24] OBSOLETE3, [17:16] AXI2_RANGE_PROT_BITS_1, [11:8] AXI2_RANGE_WID_CHECK_BITS_ID_LOOKUP_0, [3:0] AXI2_RANGE_RID_CHECK_BITS_ID_LOOKUP_0
0x4000D474 DENALI_CTL_285
  [31:16] AXI2_RANGE_WID_CHECK_BITS_1, [15:0] AXI2_RANGE_RID_CHECK_BITS_1
0x4000D478 DENALI_CTL_286
  [31:24] OBSOLETE3, [17:16] AXI2_RANGE_PROT_BITS_2, [11:8] AXI2_RANGE_WID_CHECK_BITS_ID_LOOKUP_1, [3:0] AXI2_RANGE_RID_CHECK_BITS_ID_LOOKUP_1
0x4000D47C DENALI_CTL_287
  [31:16] AXI2_RANGE_WID_CHECK_BITS_2, [15:0] AXI2_RANGE_RID_CHECK_BITS_2
0x4000D480 DENALI_CTL_288
  [31:24] OBSOLETE3, [17:16] AXI2_RANGE_PROT_BITS_3, [11:8] AXI2_RANGE_WID_CHECK_BITS_ID_LOOKUP_2, [3:0] AXI2_RANGE_RID_CHECK_BITS_ID_LOOKUP_2
0x4000D484 DENALI_CTL_289
  [31:16] AXI2_RANGE_WID_CHECK_BITS_3, [15:0] AXI2_RANGE_RID_CHECK_BITS_3
0x4000D488 DENALI_CTL_290
  [31:24] OBSOLETE3, [17:16] AXI2_RANGE_PROT_BITS_4, [11:8] AXI2_RANGE_WID_CHECK_BITS_ID_LOOKUP_3, [3:0] AXI2_RANGE_RID_CHECK_BITS_ID_LOOKUP_3
0x4000D48C DENALI_CTL_291
  [31:16] AXI2_RANGE_WID_CHECK_BITS_4, [15:0] AXI2_RANGE_RID_CHECK_BITS_4
0x4000D490 DENALI_CTL_292
  [31:24] OBSOLETE3, [17:16] AXI2_RANGE_PROT_BITS_5, [11:8] AXI2_RANGE_WID_CHECK_BITS_ID_LOOKUP_4, [3:0] AXI2_RANGE_RID_CHECK_BITS_ID_LOOKUP_4
0x4000D494 DENALI_CTL_293
  [31:16] AXI2_RANGE_WID_CHECK_BITS_5, [15:0] AXI2_RANGE_RID_CHECK_BITS_5
0x4000D498 DENALI_CTL_294
  [31:24] OBSOLETE3, [17:16] AXI2_RANGE_PROT_BITS_6, [11:8] AXI2_RANGE_WID_CHECK_BITS_ID_LOOKUP_5, [3:0] AXI2_RANGE_RID_CHECK_BITS_ID_LOOKUP_5
0x4000D49C DENALI_CTL_295
  [31:16] AXI2_RANGE_WID_CHECK_BITS_6, [15:0] AXI2_RANGE_RID_CHECK_BITS_6
0x4000D4A0 DENALI_CTL_296
  [31:24] OBSOLETE3, [17:16] AXI2_RANGE_PROT_BITS_7, [11:8] AXI2_RANGE_WID_CHECK_BITS_ID_LOOKUP_6, [3:0] AXI2_RANGE_RID_CHECK_BITS_ID_LOOKUP_6
0x4000D4A4 DENALI_CTL_297
  [31:16] AXI2_RANGE_WID_CHECK_BITS_7, [15:0] AXI2_RANGE_RID_CHECK_BITS_7
0x4000D4A8 DENALI_CTL_298
  [31:24] OBSOLETE3, [17:16] AXI2_RANGE_PROT_BITS_8, [11:8] AXI2_RANGE_WID_CHECK_BITS_ID_LOOKUP_7, [3:0] AXI2_RANGE_RID_CHECK_BITS_ID_LOOKUP_7
0x4000D4AC DENALI_CTL_299
  [31:16] AXI2_RANGE_WID_CHECK_BITS_8, [15:0] AXI2_RANGE_RID_CHECK_BITS_8
0x4000D4B0 DENALI_CTL_300
  [31:24] OBSOLETE3, [17:16] AXI2_RANGE_PROT_BITS_9, [11:8] AXI2_RANGE_WID_CHECK_BITS_ID_LOOKUP_8, [3:0] AXI2_RANGE_RID_CHECK_BITS_ID_LOOKUP_8
0x4000D4B4 DENALI_CTL_301
  [31:16] AXI2_RANGE_WID_CHECK_BITS_9, [15:0] AXI2_RANGE_RID_CHECK_BITS_9
0x4000D4B8 DENALI_CTL_302
  [31:24] OBSOLETE3, [17:16] AXI2_RANGE_PROT_BITS_10, [11:8] AXI2_RANGE_WID_CHECK_BITS_ID_LOOKUP_9, [3:0] AXI2_RANGE_RID_CHECK_BITS_ID_LOOKUP_9
0x4000D4BC DENALI_CTL_303
  [31:16] AXI2_RANGE_WID_CHECK_BITS_10, [15:0] AXI2_RANGE_RID_CHECK_BITS_10
0x4000D4C0 DENALI_CTL_304
  [31:24] OBSOLETE3, [17:16] AXI2_RANGE_PROT_BITS_11, [11:8] AXI2_RANGE_WID_CHECK_BITS_ID_LOOKUP_10, [3:0] AXI2_RANGE_RID_CHECK_BITS_ID_LOOKUP_10
0x4000D4C4 DENALI_CTL_305
  [31:16] AXI2_RANGE_WID_CHECK_BITS_11, [15:0] AXI2_RANGE_RID_CHECK_BITS_11
0x4000D4C8 DENALI_CTL_306
  [31:24] OBSOLETE3, [17:16] AXI2_RANGE_PROT_BITS_12, [11:8] AXI2_RANGE_WID_CHECK_BITS_ID_LOOKUP_11, [3:0] AXI2_RANGE_RID_CHECK_BITS_ID_LOOKUP_11
0x4000D4CC DENALI_CTL_307
  [31:16] AXI2_RANGE_WID_CHECK_BITS_12, [15:0] AXI2_RANGE_RID_CHECK_BITS_12
0x4000D4D0 DENALI_CTL_308
  [31:24] OBSOLETE3, [17:16] AXI2_RANGE_PROT_BITS_13, [11:8] AXI2_RANGE_WID_CHECK_BITS_ID_LOOKUP_12, [3:0] AXI2_RANGE_RID_CHECK_BITS_ID_LOOKUP_12
0x4000D4D4 DENALI_CTL_309
  [31:16] AXI2_RANGE_WID_CHECK_BITS_13, [15:0] AXI2_RANGE_RID_CHECK_BITS_13
0x4000D4D8 DENALI_CTL_310
  [31:24] OBSOLETE3, [17:16] AXI2_RANGE_PROT_BITS_14, [11:8] AXI2_RANGE_WID_CHECK_BITS_ID_LOOKUP_13, [3:0] AXI2_RANGE_RID_CHECK_BITS_ID_LOOKUP_13
0x4000D4DC DENALI_CTL_311
  [31:16] AXI2_RANGE_WID_CHECK_BITS_14, [15:0] AXI2_RANGE_RID_CHECK_BITS_14
0x4000D4E0 DENALI_CTL_312
  [31:24] OBSOLETE3, [17:16] AXI2_RANGE_PROT_BITS_15, [11:8] AXI2_RANGE_WID_CHECK_BITS_ID_LOOKUP_14, [3:0] AXI2_RANGE_RID_CHECK_BITS_ID_LOOKUP_14
0x4000D4E4 DENALI_CTL_313
  [31:16] AXI2_RANGE_WID_CHECK_BITS_15, [15:0] AXI2_RANGE_RID_CHECK_BITS_15
0x4000D4E8 DENALI_CTL_314
  [31:24] OBSOLETE3, [17:16] AXI3_RANGE_PROT_BITS_0, [11:8] AXI2_RANGE_WID_CHECK_BITS_ID_LOOKUP_15, [3:0] AXI2_RANGE_RID_CHECK_BITS_ID_LOOKUP_15
0x4000D4EC DENALI_CTL_315
  [31:16] AXI3_RANGE_WID_CHECK_BITS_0, [15:0] AXI3_RANGE_RID_CHECK_BITS_0
0x4000D4F0 DENALI_CTL_316
  [31:24] OBSOLETE3, [17:16] AXI3_RANGE_PROT_BITS_1, [11:8] AXI3_RANGE_WID_CHECK_BITS_ID_LOOKUP_0, [3:0] AXI3_RANGE_RID_CHECK_BITS_ID_LOOKUP_0
0x4000D4F4 DENALI_CTL_317
  [31:16] AXI3_RANGE_WID_CHECK_BITS_1, [15:0] AXI3_RANGE_RID_CHECK_BITS_1
0x4000D4F8 DENALI_CTL_318
  [31:24] OBSOLETE3, [17:16] AXI3_RANGE_PROT_BITS_2, [11:8] AXI3_RANGE_WID_CHECK_BITS_ID_LOOKUP_1, [3:0] AXI3_RANGE_RID_CHECK_BITS_ID_LOOKUP_1
0x4000D4FC DENALI_CTL_319
  [31:16] AXI3_RANGE_WID_CHECK_BITS_2, [15:0] AXI3_RANGE_RID_CHECK_BITS_2
0x4000D500 DENALI_CTL_320
  [31:24] OBSOLETE3, [17:16] AXI3_RANGE_PROT_BITS_3, [11:8] AXI3_RANGE_WID_CHECK_BITS_ID_LOOKUP_2, [3:0] AXI3_RANGE_RID_CHECK_BITS_ID_LOOKUP_2
0x4000D504 DENALI_CTL_321
  [31:16] AXI3_RANGE_WID_CHECK_BITS_3, [15:0] AXI3_RANGE_RID_CHECK_BITS_3
0x4000D508 DENALI_CTL_322
  [31:24] OBSOLETE3, [17:16] AXI3_RANGE_PROT_BITS_4, [11:8] AXI3_RANGE_WID_CHECK_BITS_ID_LOOKUP_3, [3:0] AXI3_RANGE_RID_CHECK_BITS_ID_LOOKUP_3
0x4000D50C DENALI_CTL_323
  [31:16] AXI3_RANGE_WID_CHECK_BITS_4, [15:0] AXI3_RANGE_RID_CHECK_BITS_4
0x4000D510 DENALI_CTL_324
  [31:24] OBSOLETE3, [17:16] AXI3_RANGE_PROT_BITS_5, [11:8] AXI3_RANGE_WID_CHECK_BITS_ID_LOOKUP_4, [3:0] AXI3_RANGE_RID_CHECK_BITS_ID_LOOKUP_4
0x4000D514 DENALI_CTL_325
  [31:16] AXI3_RANGE_WID_CHECK_BITS_5, [15:0] AXI3_RANGE_RID_CHECK_BITS_5
0x4000D518 DENALI_CTL_326
  [31:24] OBSOLETE3, [17:16] AXI3_RANGE_PROT_BITS_6, [11:8] AXI3_RANGE_WID_CHECK_BITS_ID_LOOKUP_5, [3:0] AXI3_RANGE_RID_CHECK_BITS_ID_LOOKUP_5
0x4000D51C DENALI_CTL_327
  [31:16] AXI3_RANGE_WID_CHECK_BITS_6, [15:0] AXI3_RANGE_RID_CHECK_BITS_6
0x4000D520 DENALI_CTL_328
  [31:24] OBSOLETE3, [17:16] AXI3_RANGE_PROT_BITS_7, [11:8] AXI3_RANGE_WID_CHECK_BITS_ID_LOOKUP_6, [3:0] AXI3_RANGE_RID_CHECK_BITS_ID_LOOKUP_6
0x4000D524 DENALI_CTL_329
  [31:16] AXI3_RANGE_WID_CHECK_BITS_7, [15:0] AXI3_RANGE_RID_CHECK_BITS_7
0x4000D528 DENALI_CTL_330
  [31:24] OBSOLETE3, [17:16] AXI3_RANGE_PROT_BITS_8, [11:8] AXI3_RANGE_WID_CHECK_BITS_ID_LOOKUP_7, [3:0] AXI3_RANGE_RID_CHECK_BITS_ID_LOOKUP_7
0x4000D52C DENALI_CTL_331
  [31:16] AXI3_RANGE_WID_CHECK_BITS_8, [15:0] AXI3_RANGE_RID_CHECK_BITS_8
0x4000D530 DENALI_CTL_332
  [31:24] OBSOLETE3, [17:16] AXI3_RANGE_PROT_BITS_9, [11:8] AXI3_RANGE_WID_CHECK_BITS_ID_LOOKUP_8, [3:0] AXI3_RANGE_RID_CHECK_BITS_ID_LOOKUP_8
0x4000D534 DENALI_CTL_333
  [31:16] AXI3_RANGE_WID_CHECK_BITS_9, [15:0] AXI3_RANGE_RID_CHECK_BITS_9
0x4000D538 DENALI_CTL_334
  [31:24] OBSOLETE3, [17:16] AXI3_RANGE_PROT_BITS_10, [11:8] AXI3_RANGE_WID_CHECK_BITS_ID_LOOKUP_9, [3:0] AXI3_RANGE_RID_CHECK_BITS_ID_LOOKUP_9
0x4000D53C DENALI_CTL_335
  [31:16] AXI3_RANGE_WID_CHECK_BITS_10, [15:0] AXI3_RANGE_RID_CHECK_BITS_10
0x4000D540 DENALI_CTL_336
  [31:24] OBSOLETE3, [17:16] AXI3_RANGE_PROT_BITS_11, [11:8] AXI3_RANGE_WID_CHECK_BITS_ID_LOOKUP_10, [3:0] AXI3_RANGE_RID_CHECK_BITS_ID_LOOKUP_10
0x4000D544 DENALI_CTL_337
  [31:16] AXI3_RANGE_WID_CHECK_BITS_11, [15:0] AXI3_RANGE_RID_CHECK_BITS_11
0x4000D548 DENALI_CTL_338
  [31:24] OBSOLETE3, [17:16] AXI3_RANGE_PROT_BITS_12, [11:8] AXI3_RANGE_WID_CHECK_BITS_ID_LOOKUP_11, [3:0] AXI3_RANGE_RID_CHECK_BITS_ID_LOOKUP_11
0x4000D54C DENALI_CTL_339
  [31:16] AXI3_RANGE_WID_CHECK_BITS_12, [15:0] AXI3_RANGE_RID_CHECK_BITS_12
0x4000D550 DENALI_CTL_340
  [31:24] OBSOLETE3, [17:16] AXI3_RANGE_PROT_BITS_13, [11:8] AXI3_RANGE_WID_CHECK_BITS_ID_LOOKUP_12, [3:0] AXI3_RANGE_RID_CHECK_BITS_ID_LOOKUP_12
0x4000D554 DENALI_CTL_341
  [31:16] AXI3_RANGE_WID_CHECK_BITS_13, [15:0] AXI3_RANGE_RID_CHECK_BITS_13
0x4000D558 DENALI_CTL_342
  [31:24] OBSOLETE3, [17:16] AXI3_RANGE_PROT_BITS_14, [11:8] AXI3_RANGE_WID_CHECK_BITS_ID_LOOKUP_13, [3:0] AXI3_RANGE_RID_CHECK_BITS_ID_LOOKUP_13
0x4000D55C DENALI_CTL_343
  [31:16] AXI3_RANGE_WID_CHECK_BITS_14, [15:0] AXI3_RANGE_RID_CHECK_BITS_14
0x4000D560 DENALI_CTL_344
  [31:24] OBSOLETE3, [17:16] AXI3_RANGE_PROT_BITS_15, [11:8] AXI3_RANGE_WID_CHECK_BITS_ID_LOOKUP_14, [3:0] AXI3_RANGE_RID_CHECK_BITS_ID_LOOKUP_14
0x4000D564 DENALI_CTL_345
  [31:16] AXI3_RANGE_WID_CHECK_BITS_15, [15:0] AXI3_RANGE_RID_CHECK_BITS_15
0x4000D568 DENALI_CTL_346
  [30:24] AXI0_BDW, [18:16] ARB_CMD_Q_THRESHOLD, [11:8] AXI3_RANGE_WID_CHECK_BITS_ID_LOOKUP_15, [3:0] AXI3_RANGE_RID_CHECK_BITS_ID_LOOKUP_15
0x4000D56C DENALI_CTL_347
  [24] AXI1_BDW_OVFLOW, [22:16] AXI1_BDW, [14:8] AXI0_CURRENT_BDW, [0] AXI0_BDW_OVFLOW
0x4000D570 DENALI_CTL_348
  [30:24] AXI2_CURRENT_BDW, [16] AXI2_BDW_OVFLOW, [14:8] AXI2_BDW, [6:0] AXI1_CURRENT_BDW
0x4000D574 DENALI_CTL_349
  [25:24] CKE_STATUS, [22:16] AXI3_CURRENT_BDW, [8] AXI3_BDW_OVFLOW, [6:0] AXI3_BDW
0x4000D578 DENALI_CTL_350
  [31:24] DLL_RST_ADJ_DLY, [23:8] DLL_RST_DELAY, [0] MEM_RST_VALID
0x4000D57C DENALI_CTL_351
  [29:24] TDFI_RDDATA_EN, [21:16] TDFI_PHY_RDLAT, [14:8] UPDATE_ERROR_STATUS, [5:0] TDFI_PHY_WRLAT
0x4000D580 DENALI_CTL_352
  [29:16] TDFI_CTRLUPD_MAX, [11:8] TDFI_CTRLUPD_MIN, [1:0] DRAM_CLK_DISABLE
0x4000D584 DENALI_CTL_353
  [31:16] TDFI_PHYUPD_TYPE1, [15:0] TDFI_PHYUPD_TYPE0
0x4000D588 DENALI_CTL_354
  [31:16] TDFI_PHYUPD_TYPE3, [15:0] TDFI_PHYUPD_TYPE2
0x4000D58C DENALI_CTL_355
  [31:16] OBSOLETE1, [13:0] TDFI_PHYUPD_RESP
0x4000D590 DENALI_CTL_356
  [31:0] TDFI_CTRLUPD_INTERVAL
0x4000D594 DENALI_CTL_357
  [27:24] TDFI_DRAM_CLK_DISABLE, [19:16] TDFI_CTRL_DELAY, [13:8] WRLAT_ADJ, [5:0] RDLAT_ADJ
0x4000D598 DENALI_CTL_358
  [25:16] TDFI_WRLVL_WW, [15:8] TDFI_WRLVL_EN, [3:0] TDFI_DRAM_CLK_ENABLE
0x4000D59C DENALI_CTL_359
  [31:0] TDFI_WRLVL_RESP
0x4000D5A0 DENALI_CTL_360
  [31:0] TDFI_WRLVL_MAX
0x4000D5A4 DENALI_CTL_361
  [31:24] TDFI_WRLVL_RESPLAT, [23:16] TDFI_WRLVL_DLL, [15:0] DFI_WRLVL_MAX_DELAY
0x4000D5A8 DENALI_CTL_362
  [31:24] TDFI_RDLVL_LOAD, [23:16] TDFI_RDLVL_DLL, [15:8] TDFI_RDLVL_EN, [7:0] TDFI_WRLVL_LOAD
0x4000D5AC DENALI_CTL_363
  [31:24] OBSOLETE2, [23:8] RDLVL_MAX_DELAY, [7:0] TDFI_RDLVL_RESPLAT
0x4000D5B0 DENALI_CTL_364
  [25:16] TDFI_RDLVL_RR, [15:0] RDLVL_GATE_MAX_DELAY
0x4000D5B4 DENALI_CTL_365
  [31:0] TDFI_RDLVL_RESP
0x4000D5B8 DENALI_CTL_366
  [31:24] OBSOLETE1, [19:0] RDLVL_RESP_MASK
0x4000D5BC DENALI_CTL_367
  [24] RDLVL_EN, [19:0] RDLVL_GATE_RESP_MASK
0x4000D5C0 DENALI_CTL_368
  [31:16] OBSOLETE2, [8] RDLVL_GATE_PREAMBLE_CHECK_EN, [0] RDLVL_GATE_EN
0x4000D5C4 DENALI_CTL_369
  [31:0] TDFI_RDLVL_MAX
0x4000D5C8 DENALI_CTL_370
  [29:16] RDLVL_ERROR_STATUS, [11:8] RDLVL_GATE_DQ_0_COUNT, [3:0] RDLVL_DQ_0_COUNT
0x4000D5CC DENALI_CTL_371
  [31:16] RDLVL_GATE_INTERVAL, [15:0] RDLVL_INTERVAL
0x4000D5D0 DENALI_CTL_372
  [24] OPTIMAL_RMODW_EN, [23:16] MEMCD_RMODW_FIFO_PTR_WIDTH, [15:8] MEMCD_RMODW_FIFO_DEPTH, [2:0] TDFI_PHY_WRDATA
0x4000D5D4 DENALI_CTL_373
0x4000D5D8 DENALI_CTL_374
  [8n] AXI{n}_ALL_STROBES_USED_ENABLE (n=0..3)
